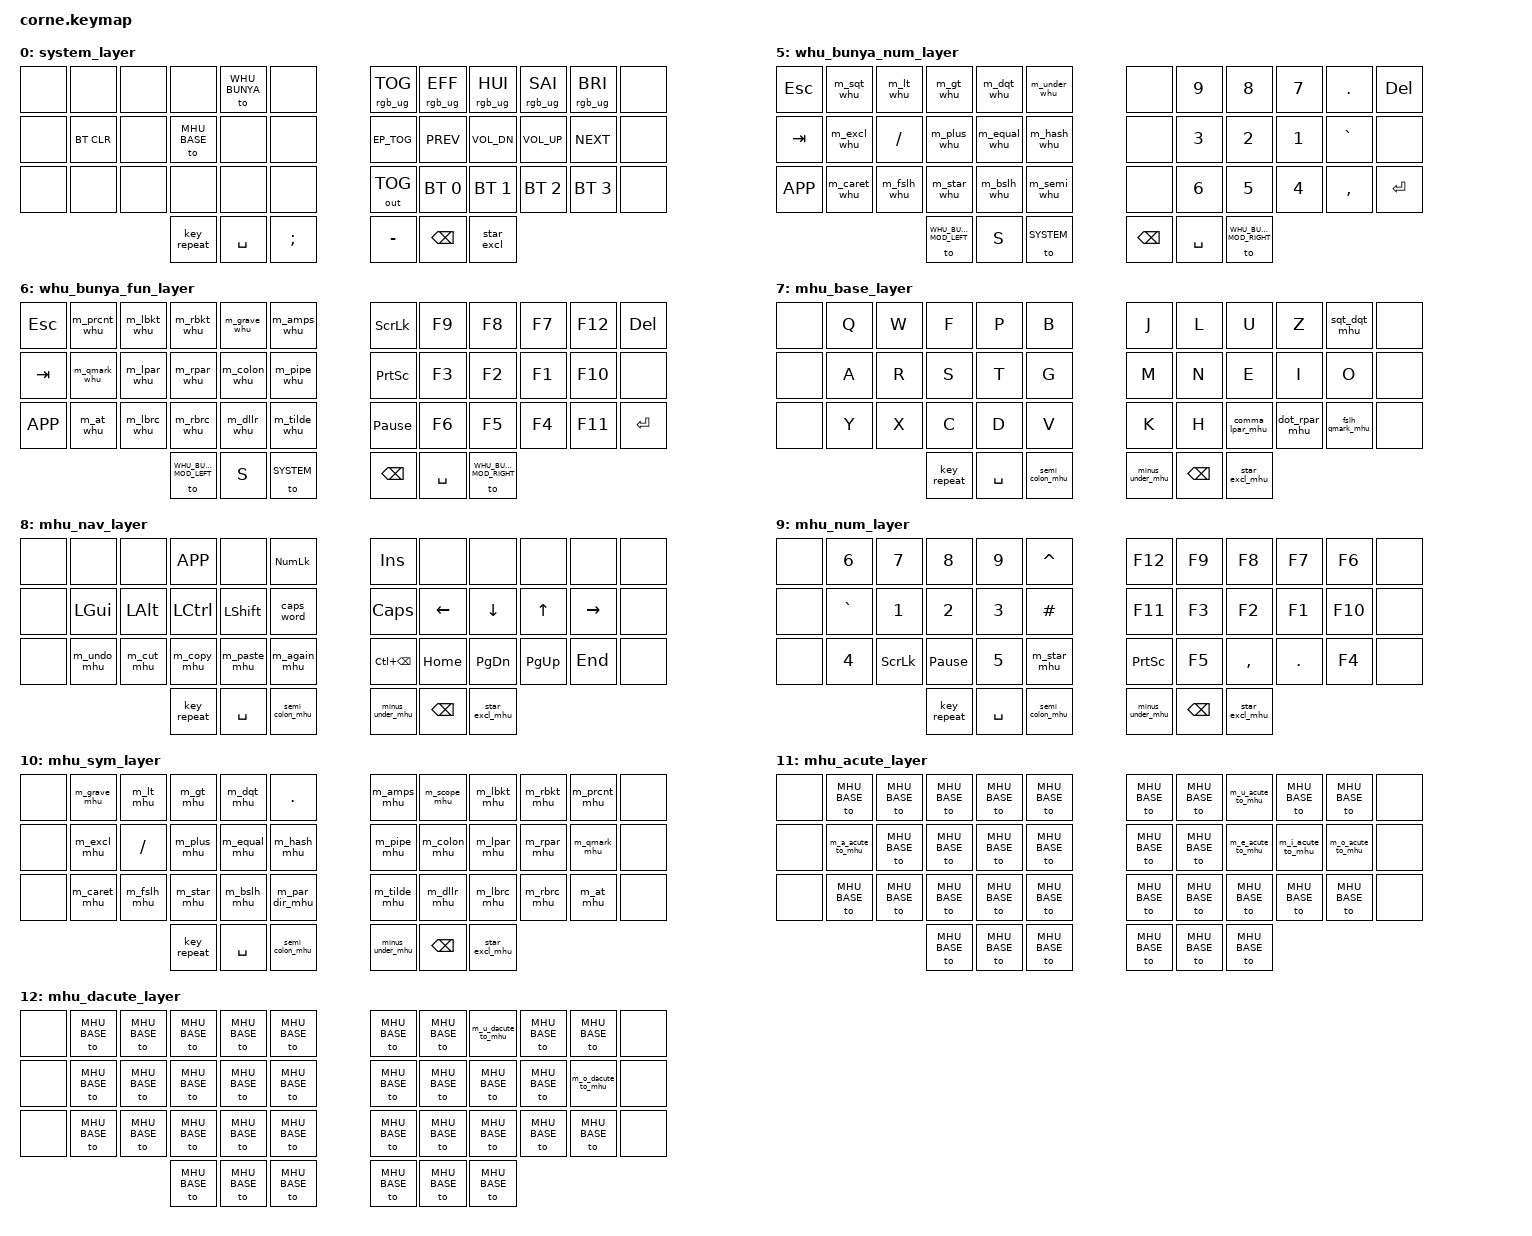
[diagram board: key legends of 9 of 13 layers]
/*
 * Copyright (c) 2022 The ZMK Contributors
 *
 * SPDX-License-Identifier: MIT
 */

#include <behaviors.dtsi>
#include <dt-bindings/zmk/keys.h>
#include <dt-bindings/zmk/bt.h>
#include <dt-bindings/zmk/rgb.h>
#include <dt-bindings/zmk/outputs.h>
#include <dt-bindings/zmk/ext_power.h>

#include "timing.h"
#include "layers.h"
#include "punctuation_en.h"
#include "punctuation_hu.h"
#include "whu-macros.h"
#include "mhu.h"
#include "bunya-dtm-hu.h"
#include "sequitap.h"

// Left Side
#define TIL  3 // Top Index finger Left
#define TML  2
#define HIL 13 // Home Index Left
#define HML 12
#define HRL 11
#define HPL 10
#define BIL 23 // Bottom Index Left
#define BML 22
#define BRL 21
#define BPL 20
#define OTL 32 // Outer Thumb Left
#define ITL 31 // Inner Thumb Left

// Right Side
#define TIR  6 // Top Index finger Right
#define TMR  7
#define HIR 16 // Home Index Right
#define HMR 17
#define HRR 18
#define HPR 19
#define BIR 26 // Bottom Index Right
#define BMR 27
#define BRR 28
#define BPR 29
#define OTR 37 // Outer Thumb Right
#define ITR 38 // Inner Thumb Right

/ {
    combos { // TODO Remove all combos if possible
        compatible = "zmk,combos";

        combo_to_system {
            timeout-ms = <TIMEOUT_MS>;
            key-positions = <2 3 4>;
            bindings = <&to SYSTEM >;
            layers = <MHU_LAYER_SET>;
        };

        combo_globe_right {
            timeout-ms = <TIMEOUT_MS>;
            key-positions = <40 18>;
            bindings = <&skq GLOBE>;
            layers = <MHU_LAYER_SET>;
        };
        combo_globe_left {
            timeout-ms = <TIMEOUT_MS>;
            key-positions = <37 17>;
            bindings = <&skq GLOBE>;
            layers = <MHU_LAYER_SET>;
        };
        combo_shft_right {
            timeout-ms = <TIMEOUT_MS>;
            key-positions = <40 19>;
            bindings = <&skq LSHFT>;
            layers = <MHU_LAYER_SET>;
        };
        combo_shft_left {
            timeout-ms = <TIMEOUT_MS>;
            key-positions = <37 16>;
            bindings = <&skq LSHFT>;
            layers = <MHU_LAYER_SET>;
        };
        combo_ctrl_right {
            timeout-ms = <TIMEOUT_MS>;
            key-positions = <40 20>;
            bindings = <&skq LCTRL>;
            layers = <MHU_LAYER_SET>;
        };
        combo_ctrl_left {
            timeout-ms = <TIMEOUT_MS>;
            key-positions = <37 15>;
            bindings = <&skq LCTRL>;
            layers = <MHU_LAYER_SET>;
        };
        combo_alt_right {
            timeout-ms = <TIMEOUT_MS>;
            key-positions = <40 21>;
            bindings = <&skq LALT>;
            layers = <MHU_LAYER_SET>;
        };
        combo_alt_left {
            timeout-ms = <TIMEOUT_MS>;
            key-positions = <37 14>;
            bindings = <&skq LALT>;
            layers = <MHU_LAYER_SET>;
        }; 
        combo_gui_right {
            timeout-ms = <TIMEOUT_MS>;
            key-positions = <40 22>;
            bindings = <&skq LGUI>;
            layers = <MHU_LAYER_SET>;
        };
        combo_gui_left {
            timeout-ms = <TIMEOUT_MS>;
            key-positions = <37 13>;
            bindings = <&skq LGUI>;
            layers = <MHU_LAYER_SET>;
        };
        
        combo_enter_right {
            timeout-ms = <TIMEOUT_MS>;
            key-positions = <32 33>;
            bindings = <&kp RET>;
            layers = <MHU_LAYER_SET>;
        };
        combo_esc_left {
            timeout-ms = <TIMEOUT_MS>;
            key-positions = <26 27>;
            bindings = <&kp ESC>;
            layers = <MHU_LAYER_SET>;
        };
        combo_tab_left {
            timeout-ms = <TIMEOUT_MS>;
            key-positions = <14 15>;
            bindings = <&kp TAB>;
            layers = <MHU_LAYER_SET>;
        };
        combo_del_right {
            timeout-ms = <TIMEOUT_MS>;
            key-positions = <20 21>;
            bindings = <&kp DEL>;
            layers = <MHU_LAYER_SET>;
        };
    };

    keymap {
        compatible = "zmk,keymap";

        system_layer {
// SYSTEM
            bindings = <
    &none    &none       &none  &none         &to WHU_BUNYA  &none             &rgb_ug RGB_TOG  &rgb_ug RGB_EFF  &rgb_ug RGB_HUI  &rgb_ug RGB_SAI  &rgb_ug RGB_BRI    &none
    &none    &bt BT_CLR  &none  &to MHU_BASE  &none          &none             &kp EP_TOG       &kp C_PREV       &kp C_VOL_DN     &kp C_VOL_UP     &kp C_NEXT         &none
    &none    &none       &none  &none         &none          &none             &out OUT_TOG     &bt BT_SEL 0     &bt BT_SEL 1     &bt BT_SEL 2     &bt BT_SEL 3       &none
                                &key_repeat   &kp SPACE      &kp SEMI          &kp MINUS        &kp BSPC         &star_excl
            >;
        };

// BUNYA-DTM
        whu_b_layer { bindings = < BUNYA_DTM(WHU) >; };
        whu_b_mod_left { bindings = < MOD_LEFT(WHU, WHU_BUNYA) >; };
        whu_b_mod_right { bindings = < MOD_RIGHT(WHU, WHU_BUNYA) >; };
        whu_b_nav_layer { bindings = < NAV(WHU, WHU_BUNYA) >; };

        whu_bunya_num_layer { // TODO put somewhere "&kp KP_NUMLOCK" and creare a numpad layer 
// WHU_BUNYA-DTM_NUM, KP_DOT would be better here instad of DOT, but num lock state interferes with KP_DOT.
            bindings = <
    &kp ESC    &m_sqt_whu    &m_lt_whu    &m_gt_whu               &m_dqt_whu    &m_under_whu         &none     &kp N9     &kp N8                  &kp N7  &kp DOT     &kp DEL
    &kp TAB    &m_excl_whu   &kp FSLH     &m_plus_whu             &m_equal_whu  &m_hash_whu          &none     &kp N3     &kp N2                  &kp N1  &kp GRAVE   &none
    &kp K_APP  &m_caret_whu  &m_fslh_whu  &m_star_whu             &m_bslh_whu   &m_semi_whu          &none     &kp N6     &kp N5                  &kp N4  &kp COMMA   &kp RET
                                          &to WHU_BUNYA_MOD_LEFT  &kp S         &to SYSTEM           &kp BSPC  &kp SPACE  &to WHU_BUNYA_MOD_RIGHT
            >;
        };

        whu_bunya_fun_layer {
// WHU_BUNYA-DTM_FUN
            bindings = <
   &kp ESC    &m_prcnt_whu  &m_lbkt_whu  &m_rbkt_whu             &m_grave_whu  &m_amps_whu           &kp SLCK        &kp F9     &kp F8                   &kp F7 &kp F12 &kp DEL
   &kp TAB    &m_qmark_whu  &m_lpar_whu  &m_rpar_whu             &m_colon_whu  &m_pipe_whu           &kp PSCRN       &kp F3     &kp F2                   &kp F1 &kp F10 &none
   &kp K_APP  &m_at_whu     &m_lbrc_whu  &m_rbrc_whu             &m_dllr_whu   &m_tilde_whu          &kp PAUSE_BREAK &kp F6     &kp F5                   &kp F4 &kp F11 &kp RET
                                         &to WHU_BUNYA_MOD_LEFT  &kp S         &to SYSTEM            &kp BSPC        &kp SPACE  &to WHU_BUNYA_MOD_RIGHT
            >;
        };

        mhu_base_layer {
// COLEMAK-DH
            bindings = <
    &none    &kp Q   &kp W        &kp F      &kp P            &kp B           &kp J   &kp L             &kp U            &kp Z           &sqt_dqt_mhu       &none
    &none    &kp A   &kp R        &kp S      &kp T            &kp G           &kp M   &kp N             &kp E            &kp I           &kp O              &none
    &none    &kp Y   &kp X        &kp C      &kp D            &kp V           &kp K   &kp H             &comma_lpar_mhu  &dot_rpar_mhu   &fslh_qmark_mhu    &none
                     &key_repeat  &kp SPACE  &semi_colon_mhu                          &minus_under_mhu  &kp BSPC         &star_excl_mhu
            >;
        };

        mhu_nav_layer {
// MHU_NAV
            bindings = <
    &none    &none        &none          &kp K_APP    &none            &kp KP_NUMLOCK          &kp INS       &none             &none      &none           &none        &none
    &none    &kp LGUI     &kp LALT       &kp LCTRL    &kp LSHFT        &caps_word              &kp CAPS      &kp LEFT          &kp DOWN   &kp UP          &kp RIGHT    &none
    &none    &m_undo_mhu  &m_cut_mhu     &m_copy_mhu  &m_paste_mhu     &m_again_mhu            &kp LC(BSPC)  &kp HOME          &kp PG_DN  &kp PG_UP       &kp END      &none
                          &key_repeat    &kp SPACE    &semi_colon_mhu                                        &minus_under_mhu  &kp BSPC   &star_excl_mhu
            >;
        };

        mhu_num_layer {
// MHU_NUM, KP_DOT would be better here instad of DOT, but num lock state interferes with KP_DOT.
            bindings = <
    &none    &kp N6     &kp N7       &kp N8           &kp N9           &kp CARET            &kp F12    &kp F9            &kp F8     &kp F7          &kp F6       &none
    &none    &kp GRAVE  &kp N1       &kp N2           &kp N3           &kp HASH             &kp F11    &kp F3            &kp F2     &kp F1          &kp F10      &none
    &none    &kp N4     &kp SLCK     &kp PAUSE_BREAK  &kp N5           &m_star_mhu          &kp PSCRN  &kp F5            &kp COMMA  &kp DOT         &kp F4       &none
                        &key_repeat  &kp SPACE        &semi_colon_mhu                                  &minus_under_mhu  &kp BSPC   &star_excl_mhu
            >;
        };
        
        mhu_sym_layer {
// MHU_SYM
            bindings = <
    &none    &m_grave_mhu  &m_lt_mhu    &m_gt_mhu    &m_dqt_mhu       &kp DOT                 &m_amps_mhu   &m_scope_mhu      &m_lbkt_mhu  &m_rbkt_mhu     &m_prcnt_mhu     &none
    &none    &m_excl_mhu   &kp FSLH     &m_plus_mhu  &m_equal_mhu     &m_hash_mhu             &m_pipe_mhu   &m_colon_mhu      &m_lpar_mhu  &m_rpar_mhu     &m_qmark_mhu     &none
    &none    &m_caret_mhu  &m_fslh_mhu  &m_star_mhu  &m_bslh_mhu      &m_par_dir_mhu          &m_tilde_mhu  &m_dllr_mhu       &m_lbrc_mhu  &m_rbrc_mhu     &m_at_mhu        &none
                           &key_repeat  &kp SPACE    &semi_colon_mhu                                        &minus_under_mhu  &kp BSPC     &star_excl_mhu
            >;
        };

        mhu_acute_layer {
// ACUTE LAYER
            bindings = <
    &none  &to MHU_BASE       &to MHU_BASE  &to MHU_BASE  &to MHU_BASE  &to MHU_BASE           &to MHU_BASE  &to MHU_BASE  &m_u_acute_to_mhu  &to MHU_BASE       &to MHU_BASE       &none
    &none  &m_a_acute_to_mhu  &to MHU_BASE  &to MHU_BASE  &to MHU_BASE  &to MHU_BASE           &to MHU_BASE  &to MHU_BASE  &m_e_acute_to_mhu  &m_i_acute_to_mhu  &m_o_acute_to_mhu  &none
    &none  &to MHU_BASE       &to MHU_BASE  &to MHU_BASE  &to MHU_BASE  &to MHU_BASE           &to MHU_BASE  &to MHU_BASE  &to MHU_BASE       &to MHU_BASE       &to MHU_BASE       &none
                              &to MHU_BASE  &to MHU_BASE  &to MHU_BASE                                       &to MHU_BASE  &to MHU_BASE       &to MHU_BASE
          >;
        };

        mhu_dacute_layer {
// DOUBLE ACUTE LAYER
            bindings = <
    &none    &to MHU_BASE  &to MHU_BASE  &to MHU_BASE  &to MHU_BASE  &to MHU_BASE           &to MHU_BASE  &to MHU_BASE  &m_u_dacute_to_mhu  &to MHU_BASE  &to MHU_BASE        &none
    &none    &to MHU_BASE  &to MHU_BASE  &to MHU_BASE  &to MHU_BASE  &to MHU_BASE           &to MHU_BASE  &to MHU_BASE  &to MHU_BASE        &to MHU_BASE  &m_o_dacute_to_mhu  &none
    &none    &to MHU_BASE  &to MHU_BASE  &to MHU_BASE  &to MHU_BASE  &to MHU_BASE           &to MHU_BASE  &to MHU_BASE  &to MHU_BASE        &to MHU_BASE  &to MHU_BASE        &none
                                        &to MHU_BASE  &to MHU_BASE  &to MHU_BASE                                       &to MHU_BASE  &to MHU_BASE        &to MHU_BASE
          >;                                                                                                                                                                    
        };
/*

        mhu_diaresis_layer {
// DIARESIS LAYER
            bindings = <
    &none  &to MHU_BASE    &to MHU_BASE  &to MHU_BASE  &to MHU_BASE  &to MHU_BASE           &to MHU_BASE  &to MHU_BASE  &m_u_diaresis_to_mhu  &to MHU_BASE  &to MHU_BASE          &none
    &none  &to MHU_BASE    &to MHU_BASE  &to MHU_BASE  &to MHU_BASE  &to MHU_BASE           &to MHU_BASE  &to MHU_BASE  &to MHU_BASE          &to MHU_BASE  &m_o_diaresis_to_mhu  &none
    &none  &to MHU_BASE    &to MHU_BASE  &to MHU_BASE  &to MHU_BASE  &to MHU_BASE           &to MHU_BASE  &to MHU_BASE  &to MHU_BASE          &to MHU_BASE  &to MHU_BASE          &none
                           &to MHU_BASE  &to MHU_BASE  &to MHU_BASE                                       &to MHU_BASE  &to MHU_BASE          &to MHU_BASE
          >;
        };*/
    };
};

